# AC33Mx064 register map
Vendor: ABOV Semiconductor Co., Ltd.; File version: 0.1
CPU: CM3 r1p0, little endian, no MPU, no FPU, 3 interrupt priority bits
Registers are 32-bit, read-write, reset 0x0 unless marked. A register's access mark holds for its fields unless they carry their own. Offsets are from the block's base; [hi:lo] are bit positions.

## TGECR — Timer Group Encoder Control Register
Base 0x40003140
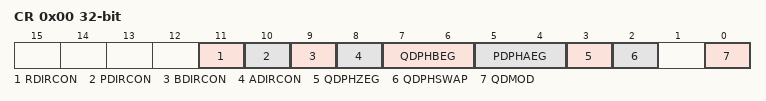
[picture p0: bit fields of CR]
0x00 CR — Timer Group Encoder Control Register
  [11] RDIRCON — Revolution counter direction control
  [10] PDIRCON — Position counter direction control
  [9] BDIRCON — Phase B counter direction control
  [8] ADIRCON — PHASE A counter direction control
  [7:6] QDPHBEG — Quadrature mode phase B count for position count
  [5:4] PDPHAEG — Quadrature mode phase A count for position count
  [3] QDPHZEG — Quadrature mode phase Z count for Revolution
  [2] QDPHSWAP — Quadrature mode phase Z count for Revolution
  [0] QDMOD — Quadrature decoder mode

## U0 — UNIVERSAL ASYNCHRONOUS RECEIVER/TRANSMITTER
Base 0x40008000
Same registers: U1 0x40008100
0x00 RBR ro — Receive Buffer Register
  [7:0] RBR — recevied/transmit data
0x00 THR wo — Transmit Data Hold Register
  [7:0] THR — recevied/transmit data
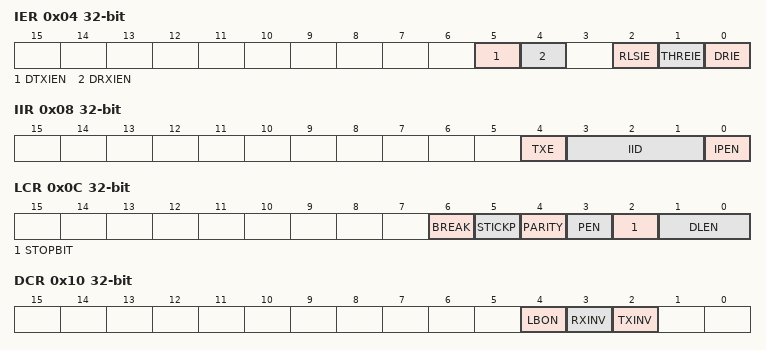
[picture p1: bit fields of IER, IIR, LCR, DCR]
0x04 IER — UART Interrupt Enable Register
  [5] DTXIEN — DMA transmit done interrupt enable
  [4] DRXIEN — DMA Receiver line status interrupt enable
  [2] RLSIE — receiver line status interrupt enable
  [1] THREIE — Transmit holding register empty interrupt enable
  [0] DRIE — Data receive interrupt enable
0x08 IIR — UART Interrupt ID Register
  [4] TXE — Interrupt source ID
  [3:1] IID — Interrupt source ID
  [0] IPEN — Interrupt pending bit
0x0C LCR — UART Line Control Register
  [6] BREAK
  [5] STICKP — STICK
  [4] PARITY
  [3] PEN — parity bit transfer enable
  [2] STOPBIT
  [1:0] DLEN — Data length in one transfer word
0x10 DCR — UART Data Control Register
  [4] LBON — Local loopback test mode enable
  [3] RXINV — Rx Data Inversion selection
  [2] TXINV — TX Data Inversion selection
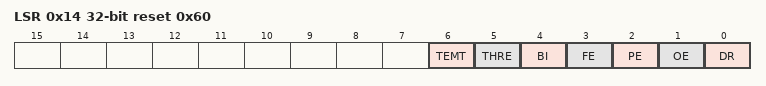
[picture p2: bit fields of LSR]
0x14 LSR reset 0x60 — UART Line Status Register
  [6] TEMT — Transmit empty
  [5] THRE — Transmit holding register empty
  [4] BI — break condition indication bit
  [3] FE — frame error
  [2] PE — parity error
  [1] OE — overrun error
  [0] DR — Data recevied
0x20 BDR — Baud rate Divisor Latch Register
  [15:0] BDR — baudrate setting
0x24 BFR — Baud rate Fraction Counter Register
  [7:0] BFR — Fraction counter value
0x30 IDTR — Inter-frame Delay Time Register
  [2:0] WAITVAL — wait time is decied by this value

## SP0 — SERIAL PERIPHERAL INTERFACE
Base 0x40009000
0x00 RDR ro — SPI n Receive Data Register
  [15:0] RDR — Data
0x00 TDR wo — SPI n Transmit Data Register
  [15:0] TDR — Data
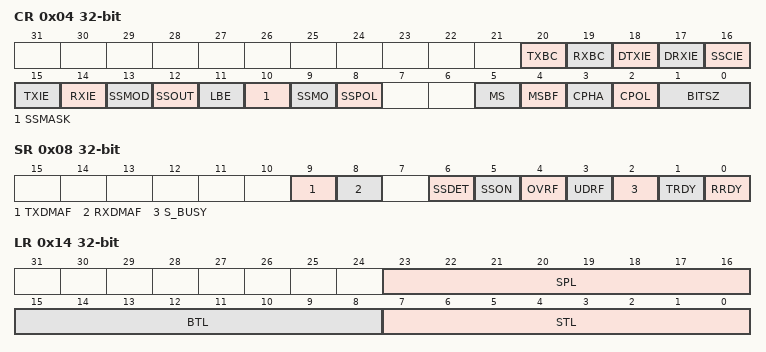
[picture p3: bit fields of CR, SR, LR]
0x04 CR — SPI n Control Register
  [20] TXBC — TX Buffer flushing bit
  [19] RXBC — RX Buffer flushing bit
  [18] DTXIE — DMA TX Done Interrupt enable bit
  [17] DRXIE — DMA Rx Deone Interrupt enable bit
  [16] SSCIE — SSn Edge Chagne Interrupt enable bit
  [15] TXIE — Transmit interrupt enable bit
  [14] RXIE — Receive interrupt enable bit
  [13] SSMOD — SS Auto/Manual Output select bit
  [12] SSOUT — SS output signal select bit
  [11] LBE — Loop-back mode select bit in master mode
  [10] SSMASK — SS Signal masking bit in slave mode
  [9] SSMO — SS output signal select bit
  [8] SSPOL — SS Signal polarity select bit
  [5] MS — master/slaver select bit
  [4] MSBF — MSB/LSB transmit select bit
  [3] CPHA — SPI clock phase bit
  [2] CPOL — SPI clock polarity bit
  [1:0] BITSZ — Transmit/receive Data bits select bit
0x08 SR — SPI n Status Register
  [9] TXDMAF — DMA transmit Operation complete flag
  [8] RXDMAF — DMA receive Operation complete flag
  [6] SSDET — The rising edge of SS detect flag
  [5] SSON — SS signal status flag
  [4] OVRF — receive overrun error flag
  [3] UDRF — transmit underrun error flag
  [2] S_BUSY ro — transmit/receive operation flag
  [1] TRDY ro — Transmit buffer empty flag
  [0] RRDY ro — receive buffer ready flag
0x0C BR — SPI n Baud Rate Register
  [15:0] BR — buadrate
0x10 EN — SPI n Enable register
  [0] ENABLE — SPI ENABLE bit
0x14 LR — SPI n delay Length Register
  [23:16] SPL — Stop delay length
  [15:8] BTL — Burst delay length
  [7:0] STL — Start delay length
